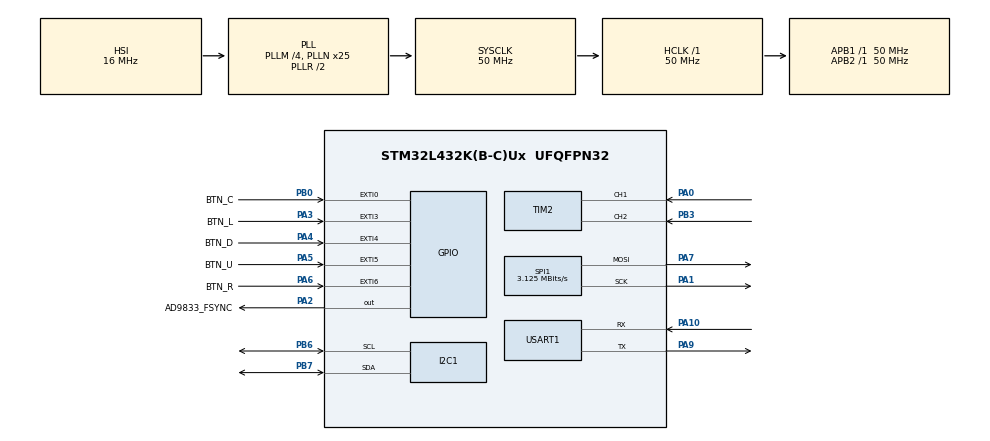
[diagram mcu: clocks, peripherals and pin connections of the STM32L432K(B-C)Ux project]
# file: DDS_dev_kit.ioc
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Dma.Request0=USART1_RX
Dma.USART1_RX.0.Direction=DMA_PERIPH_TO_MEMORY
Dma.USART1_RX.0.Instance=DMA1_Channel5
Dma.USART1_RX.0.MemDataAlignment=DMA_MDATAALIGN_BYTE
Dma.USART1_RX.0.MemInc=DMA_MINC_ENABLE
Dma.USART1_RX.0.Mode=DMA_CIRCULAR
Dma.USART1_RX.0.PeriphDataAlignment=DMA_PDATAALIGN_BYTE
Dma.USART1_RX.0.PeriphInc=DMA_PINC_DISABLE
Dma.USART1_RX.0.Priority=DMA_PRIORITY_LOW
I2C1.Timing=0x00503D58
Mcu.Family=STM32L4
Mcu.Name=STM32L432K(B-C)Ux
Mcu.Package=UFQFPN32
NVIC.DMA1_Channel5_IRQn=true\:0\:0\:false\:false\:true\:false\:true\:true
NVIC.PriorityGroup=NVIC_PRIORITYGROUP_4
PA0.Signal=S_TIM2_CH1
PA1.Mode=TX_Only_Simplex_Unidirect_Master
PA1.Signal=SPI1_SCK
PA10.Mode=Asynchronous
PA10.Signal=USART1_RX
PA13\ (JTMS-SWDIO).Mode=Serial_Wire
PA13\ (JTMS-SWDIO).Signal=SYS_JTMS-SWDIO
PA14\ (JTCK-SWCLK).Mode=Serial_Wire
PA14\ (JTCK-SWCLK).Signal=SYS_JTCK-SWCLK
PA2.GPIO_Label=AD9833_FSYNC
PA2.GPIO_Speed=GPIO_SPEED_FREQ_HIGH
PA2.PinState=GPIO_PIN_SET
PA2.Signal=GPIO_Output
PA3.GPIO_Label=BTN_L
PA3.Signal=GPXTI3
PA4.GPIO_Label=BTN_D
PA4.Signal=GPXTI4
PA5.GPIO_Label=BTN_U
PA5.Signal=GPXTI5
PA6.GPIO_Label=BTN_R
PA6.Signal=GPXTI6
PA7.Mode=TX_Only_Simplex_Unidirect_Master
PA7.Signal=SPI1_MOSI
PA9.Mode=Asynchronous
PA9.Signal=USART1_TX
PB0.GPIO_Label=BTN_C
PB0.Signal=GPXTI0
PB3\ (JTDO-TRACESWO).Signal=S_TIM2_CH2
PB6.Mode=I2C
PB6.Signal=I2C1_SCL
PB7.Mode=I2C
PB7.Signal=I2C1_SDA
ProjectManager.HeapSize=0x200
ProjectManager.StackSize=0x400
ProjectManager.TargetToolchain=STM32CubeIDE
RCC.ADCFreq_Value=16000000
RCC.AHBFreq_Value=50000000
RCC.APB1Freq_Value=50000000
RCC.APB1TimFreq_Value=50000000
RCC.APB2Freq_Value=50000000
RCC.APB2TimFreq_Value=50000000
RCC.CortexFreq_Value=50000000
RCC.HCLKFreq_Value=50000000
RCC.HSE_VALUE=8000000
RCC.HSI48_VALUE=48000000
RCC.HSI_VALUE=16000000
RCC.I2C1CLockSelection=RCC_I2C1CLKSOURCE_HSI
RCC.LSE_VALUE=32768
RCC.MSI_VALUE=4000000
RCC.PLLM=4
RCC.PLLN=25
RCC.PLLSourceVirtual=RCC_PLLSOURCE_HSI
RCC.SYSCLKFreq_VALUE=50000000
RCC.SYSCLKSource=RCC_SYSCLKSOURCE_PLLCLK
RCC.USBFreq_Value=16000000
RCC.VCOOutputFreq_Value=100000000
SH.S_TIM2_CH1.0=TIM2_CH1,Encoder_Interface
SH.S_TIM2_CH2.0=TIM2_CH2,Encoder_Interface
SPI1.BaudRatePrescaler=SPI_BAUDRATEPRESCALER_16
SPI1.CLKPolarity=SPI_POLARITY_HIGH
SPI1.CalculateBaudRate=3.125 MBits/s
SPI1.DataSize=SPI_DATASIZE_8BIT
SPI1.Direction=SPI_DIRECTION_2LINES
SPI1.Mode=SPI_MODE_MASTER
SPI1.VirtualType=VM_MASTER
USART1.VirtualMode-Asynchronous=VM_ASYNC
board=custom

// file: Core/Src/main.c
/* USER CODE BEGIN Header */
/**
  ******************************************************************************
  * @file           : main.c
  * @brief          : Main program body
  ******************************************************************************
  * @attention
  *
  * Copyright (c) 2025 STMicroelectronics.
  * All rights reserved.
  *
  * This software is licensed under terms that can be found in the LICENSE file
  * in the root directory of this software component.
  * If no LICENSE file comes with this software, it is provided AS-IS.
  *
  ******************************************************************************
  */
/* USER CODE END Header */
#include "main.h"
#include "dma.h"
#include "i2c.h"
#include "spi.h"
#include "tim.h"
#include "usart.h"
#include "gpio.h"

/* USER CODE BEGIN Includes */
#include "wrapper.hpp"
/* USER CODE END Includes */

void SystemClock_Config(void);

int main(void)
{

  /* MCU Configuration--------------------------------------------------------*/

  /* Reset of all peripherals, Initializes the Flash interface and the Systick. */
  HAL_Init();

  /* Configure the system clock */
  SystemClock_Config();

  /* Initialize all configured peripherals */
  MX_GPIO_Init();
  MX_DMA_Init();
  MX_I2C1_Init();
  MX_SPI1_Init();
  MX_TIM2_Init();
  MX_USART1_UART_Init();
  /* USER CODE BEGIN 2 */
  setup();
  /* USER CODE END 2 */

  /* Infinite loop */
  /* USER CODE BEGIN WHILE */
  while (1)
  {
    loop();
    /* USER CODE END WHILE */

  }
}

void SystemClock_Config(void)
{
  RCC_OscInitTypeDef RCC_OscInitStruct = {0};
  RCC_ClkInitTypeDef RCC_ClkInitStruct = {0};

  /** Configure the main internal regulator output voltage
  */
  if (HAL_PWREx_ControlVoltageScaling(PWR_REGULATOR_VOLTAGE_SCALE1) != HAL_OK)
  {
    Error_Handler();
  }

  /** Initializes the RCC Oscillators according to the specified parameters
  * in the RCC_OscInitTypeDef structure.
  */
  RCC_OscInitStruct.OscillatorType = RCC_OSCILLATORTYPE_HSI;
  RCC_OscInitStruct.HSIState = RCC_HSI_ON;
  RCC_OscInitStruct.HSICalibrationValue = RCC_HSICALIBRATION_DEFAULT;
  RCC_OscInitStruct.PLL.PLLState = RCC_PLL_ON;
  RCC_OscInitStruct.PLL.PLLSource = RCC_PLLSOURCE_HSI;
  RCC_OscInitStruct.PLL.PLLM = 4;
  RCC_OscInitStruct.PLL.PLLN = 25;
  RCC_OscInitStruct.PLL.PLLP = RCC_PLLP_DIV7;
  RCC_OscInitStruct.PLL.PLLQ = RCC_PLLQ_DIV2;
  RCC_OscInitStruct.PLL.PLLR = RCC_PLLR_DIV2;
  if (HAL_RCC_OscConfig(&RCC_OscInitStruct) != HAL_OK)
  {
    Error_Handler();
  }

  /** Initializes the CPU, AHB and APB buses clocks
  */
  RCC_ClkInitStruct.ClockType = RCC_CLOCKTYPE_HCLK|RCC_CLOCKTYPE_SYSCLK
                              |RCC_CLOCKTYPE_PCLK1|RCC_CLOCKTYPE_PCLK2;
  RCC_ClkInitStruct.SYSCLKSource = RCC_SYSCLKSOURCE_PLLCLK;
  RCC_ClkInitStruct.AHBCLKDivider = RCC_SYSCLK_DIV1;
  RCC_ClkInitStruct.APB1CLKDivider = RCC_HCLK_DIV1;
  RCC_ClkInitStruct.APB2CLKDivider = RCC_HCLK_DIV1;

  if (HAL_RCC_ClockConfig(&RCC_ClkInitStruct, FLASH_LATENCY_3) != HAL_OK)
  {
    Error_Handler();
  }
}

void Error_Handler(void)
{
  __disable_irq();
  while (1)
  {
  }
}
